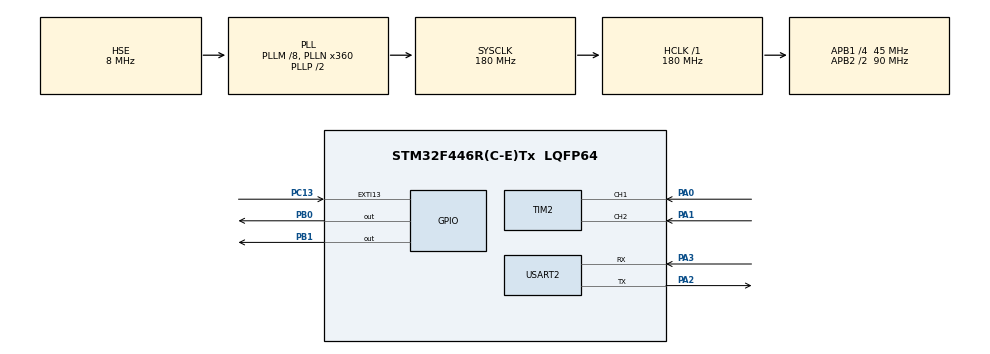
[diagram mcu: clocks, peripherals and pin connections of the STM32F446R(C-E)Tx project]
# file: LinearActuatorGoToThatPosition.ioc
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Mcu.Family=STM32F4
Mcu.Name=STM32F446R(C-E)Tx
Mcu.Package=LQFP64
NVIC.EXTI15_10_IRQn=true\:0\:0\:false\:false\:true\:true\:true\:true
NVIC.PriorityGroup=NVIC_PRIORITYGROUP_4
NVIC.TIM6_DAC_IRQn=true\:0\:0\:false\:false\:true\:true\:true\:true
NVIC.USART2_IRQn=true\:0\:0\:false\:false\:true\:true\:true\:true
PA0-WKUP.Signal=S_TIM2_CH1_ETR
PA1.Signal=S_TIM2_CH2
PA13.Mode=Serial_Wire
PA13.Signal=SYS_JTMS-SWDIO
PA14.Mode=Serial_Wire
PA14.Signal=SYS_JTCK-SWCLK
PA2.Mode=Asynchronous
PA2.Signal=USART2_TX
PA3.Mode=Asynchronous
PA3.Signal=USART2_RX
PB0.Signal=GPIO_Output
PB1.Signal=GPIO_Output
PC13.Signal=GPXTI13
PH0-OSC_IN.Mode=HSE-External-Oscillator
PH0-OSC_IN.Signal=RCC_OSC_IN
PH1-OSC_OUT.Mode=HSE-External-Oscillator
PH1-OSC_OUT.Signal=RCC_OSC_OUT
ProjectManager.HeapSize=0x200
ProjectManager.StackSize=0x400
ProjectManager.TargetToolchain=STM32CubeIDE
RCC.AHBFreq_Value=180000000
RCC.APB1CLKDivider=RCC_HCLK_DIV4
RCC.APB1Freq_Value=45000000
RCC.APB1TimFreq_Value=90000000
RCC.APB2CLKDivider=RCC_HCLK_DIV2
RCC.APB2Freq_Value=90000000
RCC.APB2TimFreq_Value=180000000
RCC.CortexFreq_Value=180000000
RCC.HCLKFreq_Value=180000000
RCC.HSE_VALUE=8000000
RCC.PLLM=8
RCC.PLLN=360
RCC.PLLSourceVirtual=RCC_PLLSOURCE_HSE
RCC.SYSCLKFreq_VALUE=180000000
RCC.SYSCLKSource=RCC_SYSCLKSOURCE_PLLCLK
RCC.USBFreq_Value=180000000
RCC.VCOOutputFreq_Value=360000000
SH.S_TIM2_CH1_ETR.0=TIM2_CH1,Encoder_Interface
SH.S_TIM2_CH2.0=TIM2_CH2,Encoder_Interface
TIM2.EncoderMode=TIM_ENCODERMODE_TI12
TIM2.IC1Filter=10
TIM2.IC2Filter=10
TIM6.Period=9
TIM6.Prescaler=8999
USART2.VirtualMode=VM_ASYNC
VP_TIM6_VS_ClockSourceINT.Mode=Enable_Timer
board=custom

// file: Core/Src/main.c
/* USER CODE BEGIN Header */
/**
  ******************************************************************************
  * @file           : main.c
  * @brief          : Main program body
  ******************************************************************************
  * @attention
  *
  * Copyright (c) 2026 STMicroelectronics.
  * All rights reserved.
  *
  * This software is licensed under terms that can be found in the LICENSE file
  * in the root directory of this software component.
  * If no LICENSE file comes with this software, it is provided AS-IS.
  *
  ******************************************************************************
  */
/* USER CODE END Header */
#include "main.h"

/* USER CODE BEGIN Includes */
#include <stdio.h>
#include <stdlib.h>
#include <string.h>
/* USER CODE END Includes */

TIM_HandleTypeDef htim2;
TIM_HandleTypeDef htim6;

UART_HandleTypeDef huart2;

void SystemClock_Config(void);
static void MX_GPIO_Init(void);
static void MX_TIM2_Init(void);
static void MX_TIM6_Init(void);
static void MX_USART2_UART_Init(void);

int main(void)
{

  /* MCU Configuration--------------------------------------------------------*/

  /* Reset of all peripherals, Initializes the Flash interface and the Systick. */
  HAL_Init();

  /* Configure the system clock */
  SystemClock_Config();

  /* Initialize all configured peripherals */
  MX_GPIO_Init();
  MX_TIM2_Init();
  MX_TIM6_Init();
  MX_USART2_UART_Init();

  /* Infinite loop */
  while (1)
  {

}

void SystemClock_Config(void)
{
  RCC_OscInitTypeDef RCC_OscInitStruct = {0};
  RCC_ClkInitTypeDef RCC_ClkInitStruct = {0};

  /** Configure the main internal regulator output voltage
  */
  __HAL_RCC_PWR_CLK_ENABLE();
  __HAL_PWR_VOLTAGESCALING_CONFIG(PWR_REGULATOR_VOLTAGE_SCALE1);

  /** Initializes the RCC Oscillators according to the specified parameters
  * in the RCC_OscInitTypeDef structure.
  */
  RCC_OscInitStruct.OscillatorType = RCC_OSCILLATORTYPE_HSE;
  RCC_OscInitStruct.HSEState = RCC_HSE_ON;
  RCC_OscInitStruct.PLL.PLLState = RCC_PLL_ON;
  RCC_OscInitStruct.PLL.PLLSource = RCC_PLLSOURCE_HSE;
  RCC_OscInitStruct.PLL.PLLM = 8;
  RCC_OscInitStruct.PLL.PLLN = 360;
  RCC_OscInitStruct.PLL.PLLP = RCC_PLLP_DIV2;
  RCC_OscInitStruct.PLL.PLLQ = 2;
  RCC_OscInitStruct.PLL.PLLR = 2;
  if (HAL_RCC_OscConfig(&RCC_OscInitStruct) != HAL_OK)
  {
    Error_Handler();
  }

  /** Activate the Over-Drive mode
  */
  if (HAL_PWREx_EnableOverDrive() != HAL_OK)
  {
    Error_Handler();
  }

  /** Initializes the CPU, AHB and APB buses clocks
  */
  RCC_ClkInitStruct.ClockType = RCC_CLOCKTYPE_HCLK|RCC_CLOCKTYPE_SYSCLK
                              |RCC_CLOCKTYPE_PCLK1|RCC_CLOCKTYPE_PCLK2;
  RCC_ClkInitStruct.SYSCLKSource = RCC_SYSCLKSOURCE_PLLCLK;
  RCC_ClkInitStruct.AHBCLKDivider = RCC_SYSCLK_DIV1;
  RCC_ClkInitStruct.APB1CLKDivider = RCC_HCLK_DIV4;
  RCC_ClkInitStruct.APB2CLKDivider = RCC_HCLK_DIV2;

  if (HAL_RCC_ClockConfig(&RCC_ClkInitStruct, FLASH_LATENCY_5) != HAL_OK)
  {
    Error_Handler();
  }
}

static void MX_TIM2_Init(void)
{

  TIM_Encoder_InitTypeDef sConfig = {0};
  TIM_MasterConfigTypeDef sMasterConfig = {0};

  htim2.Instance = TIM2;
  htim2.Init.Prescaler = 0;
  htim2.Init.CounterMode = TIM_COUNTERMODE_UP;
  htim2.Init.Period = 4294967295;
  htim2.Init.ClockDivision = TIM_CLOCKDIVISION_DIV1;
  htim2.Init.AutoReloadPreload = TIM_AUTORELOAD_PRELOAD_DISABLE;
  sConfig.EncoderMode = TIM_ENCODERMODE_TI12;
  sConfig.IC1Polarity = TIM_ICPOLARITY_RISING;
  sConfig.IC1Selection = TIM_ICSELECTION_DIRECTTI;
  sConfig.IC1Prescaler = TIM_ICPSC_DIV1;
  sConfig.IC1Filter = 10;
  sConfig.IC2Polarity = TIM_ICPOLARITY_RISING;
  sConfig.IC2Selection = TIM_ICSELECTION_DIRECTTI;
  sConfig.IC2Prescaler = TIM_ICPSC_DIV1;
  sConfig.IC2Filter = 10;
  if (HAL_TIM_Encoder_Init(&htim2, &sConfig) != HAL_OK)
  {
    Error_Handler();
  }
  sMasterConfig.MasterOutputTrigger = TIM_TRGO_RESET;
  sMasterConfig.MasterSlaveMode = TIM_MASTERSLAVEMODE_DISABLE;
  if (HAL_TIMEx_MasterConfigSynchronization(&htim2, &sMasterConfig) != HAL_OK)
  {
    Error_Handler();
  }

}

static void MX_TIM6_Init(void)
{

  TIM_MasterConfigTypeDef sMasterConfig = {0};

  htim6.Instance = TIM6;
  htim6.Init.Prescaler = 8999;
  htim6.Init.CounterMode = TIM_COUNTERMODE_UP;
  htim6.Init.Period = 9;
  htim6.Init.AutoReloadPreload = TIM_AUTORELOAD_PRELOAD_DISABLE;
  if (HAL_TIM_Base_Init(&htim6) != HAL_OK)
  {
    Error_Handler();
  }
  sMasterConfig.MasterOutputTrigger = TIM_TRGO_RESET;
  sMasterConfig.MasterSlaveMode = TIM_MASTERSLAVEMODE_DISABLE;
  if (HAL_TIMEx_MasterConfigSynchronization(&htim6, &sMasterConfig) != HAL_OK)
  {
    Error_Handler();
  }

}

static void MX_USART2_UART_Init(void)
{

  huart2.Instance = USART2;
  huart2.Init.BaudRate = 115200;
  huart2.Init.WordLength = UART_WORDLENGTH_8B;
  huart2.Init.StopBits = UART_STOPBITS_1;
  huart2.Init.Parity = UART_PARITY_NONE;
  huart2.Init.Mode = UART_MODE_TX_RX;
  huart2.Init.HwFlowCtl = UART_HWCONTROL_NONE;
  huart2.Init.OverSampling = UART_OVERSAMPLING_16;
  if (HAL_UART_Init(&huart2) != HAL_OK)
  {
    Error_Handler();
  }

}

static void MX_GPIO_Init(void)
{
  GPIO_InitTypeDef GPIO_InitStruct = {0};

  /* GPIO Ports Clock Enable */
  __HAL_RCC_GPIOC_CLK_ENABLE();
  __HAL_RCC_GPIOH_CLK_ENABLE();
  __HAL_RCC_GPIOA_CLK_ENABLE();
  __HAL_RCC_GPIOB_CLK_ENABLE();

  /*Configure GPIO pin Output Level */
  HAL_GPIO_WritePin(GPIOB, GPIO_PIN_0|GPIO_PIN_1, GPIO_PIN_RESET);

  /*Configure GPIO pin : PC13 */
  GPIO_InitStruct.Pin = GPIO_PIN_13;
  GPIO_InitStruct.Mode = GPIO_MODE_IT_RISING;
  GPIO_InitStruct.Pull = GPIO_NOPULL;
  HAL_GPIO_Init(GPIOC, &GPIO_InitStruct);

  /*Configure GPIO pins : PB0 PB1 */
  GPIO_InitStruct.Pin = GPIO_PIN_0|GPIO_PIN_1;
  GPIO_InitStruct.Mode = GPIO_MODE_OUTPUT_PP;
  GPIO_InitStruct.Pull = GPIO_NOPULL;
  GPIO_InitStruct.Speed = GPIO_SPEED_FREQ_LOW;
  HAL_GPIO_Init(GPIOB, &GPIO_InitStruct);

  /* EXTI interrupt init*/
  HAL_NVIC_SetPriority(EXTI15_10_IRQn, 0, 0);
  HAL_NVIC_EnableIRQ(EXTI15_10_IRQn);

}

void Error_Handler(void)
{
  __disable_irq();
  while (1)
  {
  }
}
